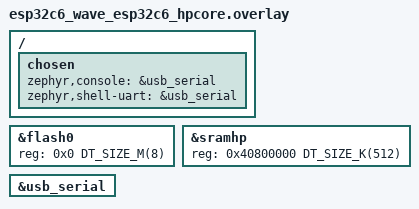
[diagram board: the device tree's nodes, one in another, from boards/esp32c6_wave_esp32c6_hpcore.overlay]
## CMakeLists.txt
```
# SPDX-License-Identifier: Apache-2.0

cmake_minimum_required(VERSION 3.20.0)

find_package(Zephyr REQUIRED HINTS $ENV{ZEPHYR_BASE})
project(ble_multitouch_sim)

target_sources(app PRIVATE src/main.c src/ble_rc.c src/touch_ipc.c)
```

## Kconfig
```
# SPDX-License-Identifier: Apache-2.0

mainmenu "BLE multi-touch simulator"

source "Kconfig.zephyr"
```

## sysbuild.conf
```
# ----> build/mcuboot/zephyr/.config.sysbuild
SB_CONFIG_MCUBOOT_MODE_OVERWRITE_ONLY=y
# SB_CONFIG_MCUBOOT_MODE_SWAP_USING_MOVE=y
# DIRECT_XIP will build two image for slot0 and slot1 for diff ADDR off 
# SB_CONFIG_MCUBOOT_MODE_DIRECT_XIP=y
# SB_CONFIG_MCUBOOT_MODE_DIRECT_XIP_WITH_REVERT=y
```

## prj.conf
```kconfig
CONFIG_BT=y
CONFIG_BT_PERIPHERAL=y
CONFIG_BT_SMP=y
CONFIG_BT_BONDABLE=y
CONFIG_BT_SETTINGS=y
CONFIG_SETTINGS=y
CONFIG_BT_BUF_ACL_TX_COUNT=8
CONFIG_BT_CONN_TX_MAX=8
CONFIG_BT_L2CAP_TX_BUF_COUNT=8
CONFIG_BT_DEVICE_NAME="Zephyr Multi-Touch"
CONFIG_BT_DEVICE_APPEARANCE=960
CONFIG_UART_NATIVE_PTY_0_ON_STDINOUT=y
CONFIG_SERIAL=y
CONFIG_SHELL=y
CONFIG_LOG=y
CONFIG_MAIN_STACK_SIZE=2048
CONFIG_SYS_CLOCK_TICKS_PER_SEC=1000

CONFIG_BT_HCI_ACL_FLOW_CONTROL=n
```

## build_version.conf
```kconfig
CONFIG_MCUBOOT_IMGTOOL_SIGN_VERSION="1.0.2+1019"
CONFIG_CUSTOM_VERSION="1.0.2"
CONFIG_CUSTOM_BUILD_NUMBER="1019"
```

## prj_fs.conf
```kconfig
# lyj config
CONFIG_WIFI_STA_EN=y

# Wi-Fi Configuration
CONFIG_WIFI=y
CONFIG_NET_L2_WIFI_SHELL=y
CONFIG_WIFI_NM=y
CONFIG_WIFI_USAGE_MODE_STA=y

# Network Configuration
CONFIG_NET_CONFIG_AUTO_INIT=n
CONFIG_NET_CONNECTION_MANAGER=y
CONFIG_NET_DHCPV4=y
CONFIG_NET_DHCPV4_SERVER=y
CONFIG_NET_IF_MAX_IPV4_COUNT=2
CONFIG_NET_IF_MAX_IPV6_COUNT=2
CONFIG_NET_IPV4=y
CONFIG_NET_L2_ETHERNET=y
CONFIG_NET_L2_WIFI_MGMT=y
CONFIG_NET_MGMT=y
CONFIG_NET_MGMT_EVENT=y
CONFIG_NET_MGMT_EVENT_INFO=y
CONFIG_NET_MGMT_EVENT_QUEUE_SIZE=10
CONFIG_NET_MGMT_EVENT_STACK_SIZE=4096
CONFIG_NET_PKT_RX_COUNT=16
CONFIG_NET_PKT_TX_COUNT=16
CONFIG_NET_SOCKETS_SERVICE_STACK_SIZE=4096
CONFIG_NET_TCP=y
CONFIG_NET_UDP=y
CONFIG_NETWORKING=y

# LOG Configuration
CONFIG_NET_LOG=y
CONFIG_NET_DHCPV4_SERVER_LOG_LEVEL_DBG=y

# websock
# Networking config
CONFIG_NETWORKING=y
CONFIG_NET_IPV4=y
#CONFIG_NET_IPV6=y
CONFIG_NET_TCP=y
CONFIG_NET_SHELL=y
CONFIG_NET_STATISTICS=y

CONFIG_NET_SOCKETS=y
CONFIG_ZVFS_POLL_MAX=10

# Network driver config
CONFIG_TEST_RANDOM_GENERATOR=y

CONFIG_NET_CONFIG_SETTINGS=y
CONFIG_NET_CONFIG_NEED_IPV4=y

# HTTP & Websocket
CONFIG_HTTP_CLIENT=y
CONFIG_WEBSOCKET_CLIENT=y

# Network debug config
CONFIG_LOG=y
CONFIG_LOG_MODE_IMMEDIATE=y
# CONFIG_NET_LOG=y
# CONFIG_NET_SOCKETS_LOG_LEVEL_DBG=y
# CONFIG_NET_HTTP_LOG_LEVEL_DBG=y
# CONFIG_NET_WEBSOCKET_LOG_LEVEL_DBG=y
# CONFIG_NET_CONTEXT_LOG_LEVEL_DBG=y
# CONFIG_NET_TCP_LOG_LEVEL_DBG=y

CONFIG_MAIN_STACK_SIZE=4096
CONFIG_HEAP_MEM_POOL_SIZE=98304

CONFIG_REQUIRES_FULL_LIBC=y
CONFIG_POSIX_API=y
CONFIG_EVENTFD=y

# Crypto Base for websocket
CONFIG_MBEDTLS=y
CONFIG_MBEDTLS_BUILTIN=y
CONFIG_MBEDTLS_MD_C=y

# 针对新版本/PSA 架构 for websocket
CONFIG_MBEDTLS_PSA_CRYPTO_C=y
CONFIG_PSA_WANT_ALG_SHA_1=y

# 内存
CONFIG_MAIN_STACK_SIZE=4096
CONFIG_MBEDTLS_ENABLE_HEAP=y
CONFIG_MBEDTLS_HEAP_SIZE=8192

CONFIG_ESP_SPIRAM=y
CONFIG_SHARED_MULTI_HEAP=y
CONFIG_SPIRAM_MODE_OCT=y
CONFIG_SPIRAM_SPEED_80M=n
# spi 4-wire MODE : 40M
# CONFIG_SPIRAM_MODE_QUAD=y
# CONFIG_SPIRAM_SPEED_40M=y
CONFIG_ESP32S3_DATA_CACHE_64KB=y
CONFIG_ESP_SPIRAM_MEMTEST=y

CONFIG_ESP32_WIFI_NET_ALLOC_SPIRAM=y

CONFIG_ZVFS_EVENTFD_MAX=5
#CONFIG_ZVFS_OPEN_MAX=10
#CONFIG_POSIX_MAX_FDS=10


######################################
#           for BLE                  #
######################################
CONFIG_BT=y
CONFIG_BT_PERIPHERAL=y
CONFIG_BT_DEVICE_NAME="小米蓝牙语音遥控器"
CONFIG_BT_DEVICE_APPEARANCE=384

CONFIG_BT_SMP=y

CONFIG_SHELL=y
CONFIG_BT_SHELL=y

CONFIG_BT_L2CAP_TX_BUF_COUNT=10
CONFIG_BT_BUF_ACL_TX_COUNT=10

CONFIG_BT_DIS=y
CONFIG_BT_DIS_PNP=y
CONFIG_BT_DIS_PNP_VID_SRC=1
CONFIG_BT_DIS_PNP_VID=0x2717
CONFIG_BT_DIS_PNP_PID=0x32b8
CONFIG_BT_DIS_PNP_VER=0x0011

CONFIG_BT_RX_STACK_SIZE=4096
CONFIG_SYSTEM_WORKQUEUE_STACK_SIZE=4096
CONFIG_BT_BUF_ACL_TX_COUNT=12


CONFIG_JSON_LIBRARY=y

CONFIG_ESP32_SW_COEXIST_ENABLE=y
CONFIG_ESP32_BT_CTLR_COEX_PHY_CODED_TX_RX_TLIM_EN=y
CONFIG_ESP32_BT_CTLR_COEX_PHY_CODED_TX_RX_TLIM_DIS=n

#SD and FS
CONFIG_DISK_DRIVER_SDMMC=y
CONFIG_DISK_ACCESS=y        
CONFIG_FILE_SYSTEM=y
CONFIG_FILE_SYSTEM_SHELL=y
CONFIG_FAT_FILESYSTEM_ELM=y
CONFIG_FS_FATFS_LFN=y
CONFIG_FS_FATFS_MAX_LFN=32

# CONFIG_FILE_SYSTEM_LITTLEFS=y
# CONFIG_FS_LITTLEFS_BLK_DEV=y
# CONFIG_FS_LITTLEFS_FMP_DEV=n

# CONFIG_FS_LITTLEFS_READ_SIZE=512
# CONFIG_FS_LITTLEFS_PROG_SIZE=512
# CONFIG_FS_LITTLEFS_CACHE_SIZE=512
# CONFIG_FS_LITTLEFS_LOOKAHEAD_SIZE=32

# CONFIG_FS_LITTLEFS_NUM_FILES=4
# CONFIG_FS_LITTLEFS_NUM_DIRS=4

CONFIG_FS_LOG_LEVEL_DBG=y

CONFIG_PSA_CRYPTO=y
CONFIG_PSA_WANT_ALG_SHA_256=y

CONFIG_FLASH=y
CONFIG_FLASH_MAP=y
CONFIG_FLASH_SHELL=y
CONFIG_FLASH_MAP_SHELL=y


CONFIG_STREAM_FLASH=y
CONFIG_IMG_MANAGER=y
CONFIG_MCUBOOT_IMG_MANAGER=y
CONFIG_MCUBOOT_SHELL=y
CONFIG_MCUBOOT_BOOTLOADER_MODE_RAM_LOAD=y
CONFIG_MCUBOOT_BOOTLOADER_MODE_RAM_LOAD_WITH_REVERT=y

CONFIG_REBOOT=y

# CONFIG_MCUBOOT_BOOTLOADER_MODE_DIRECT_XIP=y
# CONFIG_MCUBOOT_BOOTLOADER_MODE_DIRECT_XIP_WITH_REVERT=y
```

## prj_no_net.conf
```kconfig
CONFIG_WIFI_STA_EN=n
#
CONFIG_ZVFS_POLL_MAX=10

# Debug config
CONFIG_LOG=y
CONFIG_LOG_MODE_IMMEDIATE=y
# CONFIG_NET_LOG=y
# CONFIG_NET_SOCKETS_LOG_LEVEL_DBG=y
# CONFIG_NET_HTTP_LOG_LEVEL_DBG=y
# CONFIG_NET_WEBSOCKET_LOG_LEVEL_DBG=y
# CONFIG_NET_CONTEXT_LOG_LEVEL_DBG=y
# CONFIG_NET_TCP_LOG_LEVEL_DBG=y

CONFIG_MAIN_STACK_SIZE=4096
CONFIG_HEAP_MEM_POOL_SIZE=65536

CONFIG_REQUIRES_FULL_LIBC=y
CONFIG_POSIX_API=y
CONFIG_EVENTFD=y

# Crypto Base for websocket
CONFIG_MBEDTLS=y
CONFIG_MBEDTLS_BUILTIN=y
CONFIG_MBEDTLS_MD_C=y

# 针对新版本/PSA 架构 for websocket
CONFIG_MBEDTLS_PSA_CRYPTO_C=y
CONFIG_PSA_WANT_ALG_SHA_1=y

# 内存
CONFIG_MAIN_STACK_SIZE=4096
CONFIG_MBEDTLS_ENABLE_HEAP=y
CONFIG_MBEDTLS_HEAP_SIZE=8192

CONFIG_HEAP_MEM_POOL_SIZE=98304

CONFIG_ESP_SPIRAM=y
CONFIG_SHARED_MULTI_HEAP=y
CONFIG_SPIRAM_MODE_OCT=y
CONFIG_SPIRAM_SPEED_80M=y
CONFIG_ESP32S3_DATA_CACHE_64KB=y
CONFIG_ESP_SPIRAM_MEMTEST=y

CONFIG_ESP32_WIFI_NET_ALLOC_SPIRAM=y

CONFIG_ZVFS_EVENTFD_MAX=5
#CONFIG_ZVFS_OPEN_MAX=10
#CONFIG_POSIX_MAX_FDS=10


######################################
#           for BLE                  #
######################################
CONFIG_BT=y
CONFIG_BT_PERIPHERAL=y
CONFIG_BT_DEVICE_NAME="小米蓝牙语音遥控器"
CONFIG_BT_DEVICE_APPEARANCE=384

CONFIG_BT_SMP=y

CONFIG_SHELL=y
CONFIG_BT_SHELL=y

CONFIG_BT_L2CAP_TX_BUF_COUNT=10
CONFIG_BT_BUF_ACL_TX_COUNT=10

CONFIG_BT_DIS=y
CONFIG_BT_DIS_PNP=y
CONFIG_BT_DIS_PNP_VID_SRC=1
CONFIG_BT_DIS_PNP_VID=0x2717
CONFIG_BT_DIS_PNP_PID=0x32b8
CONFIG_BT_DIS_PNP_VER=0x0011

CONFIG_BT_RX_STACK_SIZE=4096
CONFIG_SYSTEM_WORKQUEUE_STACK_SIZE=4096
CONFIG_BT_BUF_ACL_TX_COUNT=12
```

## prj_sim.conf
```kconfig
# lyj config
CONFIG_WIFI_STA_EN=n


CONFIG_MAIN_STACK_SIZE=4096
CONFIG_HEAP_MEM_POOL_SIZE=65536

CONFIG_REQUIRES_FULL_LIBC=y
CONFIG_POSIX_API=y
CONFIG_EVENTFD=y

# Crypto Base for websocket
CONFIG_MBEDTLS=y
CONFIG_MBEDTLS_BUILTIN=y
CONFIG_MBEDTLS_MD_C=y

# 针对新版本/PSA 架构 for websocket
CONFIG_MBEDTLS_PSA_CRYPTO_C=y
CONFIG_PSA_WANT_ALG_SHA_1=y

# 内存
CONFIG_MAIN_STACK_SIZE=4096
CONFIG_MBEDTLS_ENABLE_HEAP=y
CONFIG_MBEDTLS_HEAP_SIZE=8192

CONFIG_HEAP_MEM_POOL_SIZE=98304

CONFIG_ZVFS_EVENTFD_MAX=5
#CONFIG_ZVFS_OPEN_MAX=10
#CONFIG_POSIX_MAX_FDS=10


######################################
#           for BLE                  #
######################################
CONFIG_BT=y
CONFIG_BT_PERIPHERAL=y
CONFIG_BT_DEVICE_NAME="小米蓝牙语音遥控器"
CONFIG_BT_DEVICE_APPEARANCE=384

CONFIG_BT_SMP=y

CONFIG_UART_NATIVE_PTY_0_ON_STDINOUT=y
CONFIG_SHELL=y
CONFIG_BT_SHELL=y

CONFIG_BT_L2CAP_TX_BUF_COUNT=10


CONFIG_BT_DIS=y
CONFIG_BT_DIS_PNP=y
CONFIG_BT_DIS_PNP_VID_SRC=1
CONFIG_BT_DIS_PNP_VID=0x2717
CONFIG_BT_DIS_PNP_PID=0x32b8
CONFIG_BT_DIS_PNP_VER=0x0011

CONFIG_BT_RX_STACK_SIZE=4096
CONFIG_SYSTEM_WORKQUEUE_STACK_SIZE=4096
CONFIG_BT_BUF_ACL_TX_COUNT=12
CONFIG_BT_BUF_EVT_RX_COUNT=16

CONFIG_BT_HCI_ACL_FLOW_CONTROL=n
CONFIG_BT_BUF_ACL_RX_SIZE=4096
CONFIG_BT_BUF_ACL_TX_SIZE=4096


CONFIG_JSON_LIBRARY=y
```

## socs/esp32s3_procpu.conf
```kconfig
CONFIG_WIFI_ESP32=y

# apsta_mode configuration
CONFIG_WIFI_SAMPLE_SSID="ACX2"
CONFIG_WIFI_SAMPLE_PSK="reinao802"
CONFIG_NET_CONFIG_PEER_IPV4_ADDR="192.168.66.155"
# CONFIG_WIFI_SAMPLE_SSID="1BE-2"
# CONFIG_WIFI_SAMPLE_PSK="12345678"
# CONFIG_NET_CONFIG_PEER_IPV4_ADDR="192.168.9.245"
#CONFIG_NET_CONFIG_HTTP_SRV_ADDR
```

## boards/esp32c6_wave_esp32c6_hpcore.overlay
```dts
/ {
	chosen {
		zephyr,console = &usb_serial;
		zephyr,shell-uart = &usb_serial;
	};
};

&flash0 {
    reg = <0x0 DT_SIZE_M(8)>;
};

&sramhp {
	reg = <0x40800000 DT_SIZE_K(512)>;
};

&usb_serial {
	status = "okay";
};
```

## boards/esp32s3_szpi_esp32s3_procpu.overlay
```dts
/ {
	chosen {
		zephyr,console = &usb_serial;
		zephyr,shell-uart = &usb_serial;
	};
};

&flash0 {
    reg = <0x0 DT_SIZE_M(16)>;
};

&psram0 {
        size = <DT_SIZE_M(8)>;
};

&usb_serial {
	status = "okay";
};
```

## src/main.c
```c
/* SPDX-License-Identifier: Apache-2.0 */

#include <zephyr/kernel.h>
#include <zephyr/logging/log.h>

#include "touch_hid.h"
#include "touch_ipc.h"

LOG_MODULE_REGISTER(main, LOG_LEVEL_INF);

int main(void)
{
	int err;

	LOG_INF("BLE multi-touch simulator starting");
	err = touch_hid_init();
	if (err) {
		LOG_ERR("Unable to start touch HID service: %d", err);
		return err;
	}

	err = touch_ipc_init();
	if (err) {
		LOG_ERR("Unable to start touch input IPC: %d", err);
		return err;
	}

	return 0;
}
```

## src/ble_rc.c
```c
/* SPDX-License-Identifier: Apache-2.0 */

#include <errno.h>
#include <stdlib.h>
#include <string.h>

#include <zephyr/bluetooth/bluetooth.h>
#include <zephyr/bluetooth/conn.h>
#include <zephyr/bluetooth/gatt.h>
#include <zephyr/bluetooth/uuid.h>
#include <zephyr/kernel.h>
#include <zephyr/logging/log.h>
#include <zephyr/shell/shell.h>
#include <zephyr/settings/settings.h>

#include "touch_hid.h"

LOG_MODULE_REGISTER(touch_hid, LOG_LEVEL_INF);

#define TOUCH_REPORT_ID 1
#define TOUCH_CONTACTS  3

struct hid_info {
	uint16_t bcd_hid;
	uint8_t country_code;
	uint8_t flags;
} __packed;

struct hid_report_ref {
	uint8_t id;
	uint8_t type;
} __packed;

struct touch_contact {
	uint8_t flags;
	uint8_t id;
	uint16_t x;
	uint16_t y;
} __packed;

struct touch_report {
	struct touch_contact contact[TOUCH_CONTACTS];
	uint8_t contact_count;
} __packed;

BUILD_ASSERT(sizeof(struct touch_report) == 19,
	     "The touch report must fit in the default 23-byte ATT MTU");

static const struct hid_info hid_info = {
	.bcd_hid = 0x0111,
	.country_code = 0,
	.flags = 0x03,
};

static const struct hid_report_ref input_report_ref = {
	.id = TOUCH_REPORT_ID,
	.type = 0x01,
};

/*
 * Report ID 1 contains three independent finger collections followed by the
 * total number of active contacts. The resulting 19-byte report fits in the
 * default 23-byte ATT MTU, so it works before a phone requests a larger MTU.
 * Coordinates use the 0..32767 HID range.
 */
static const uint8_t report_map[] = {
	0x05, 0x0d, 0x09, 0x04, 0xa1, 0x01, 0x85, TOUCH_REPORT_ID,
#define FINGER_COLLECTION \
	0x05, 0x0d, \
	0x09, 0x22, 0xa1, 0x02, \
	0x09, 0x42, 0x15, 0x00, 0x25, 0x01, 0x75, 0x01, 0x95, 0x01, 0x81, 0x02, \
	0x09, 0x32, 0x15, 0x00, 0x25, 0x01, 0x75, 0x01, 0x95, 0x01, 0x81, 0x02, \
	0x75, 0x06, 0x95, 0x01, 0x81, 0x03, \
	0x09, 0x51, 0x15, 0x00, 0x25, TOUCH_CONTACTS - 1, 0x75, 0x08, 0x95, 0x01, 0x81, 0x02, \
	0x05, 0x01, 0x09, 0x30, 0x16, 0x00, 0x00, 0x26, 0xff, 0x7f, 0x75, 0x10, 0x95, 0x01, 0x81, 0x02, \
	0x09, 0x31, 0x16, 0x00, 0x00, 0x26, 0xff, 0x7f, 0x75, 0x10, 0x95, 0x01, 0x81, 0x02, \
	0xc0
	FINGER_COLLECTION,
	FINGER_COLLECTION,
	FINGER_COLLECTION,
#undef FINGER_COLLECTION
	0x05, 0x0d, 0x09, 0x54, 0x15, 0x00, 0x25, TOUCH_CONTACTS,
	0x75, 0x08, 0x95, 0x01, 0x81, 0x02, 0xc0,
};

static struct touch_report touch_report;
/* Logical slots retain their Contact IDs. */
static struct touch_contact touch_state[TOUCH_CONTACTS];
static bool notifications_enabled;
static uint8_t control_point;
static struct bt_conn *active_conn;

static void advertising_work_handler(struct k_work *work);
K_WORK_DELAYABLE_DEFINE(advertising_work, advertising_work_handler);

static ssize_t read_hid_info(struct bt_conn *conn, const struct bt_gatt_attr *attr,
			     void *buf, uint16_t len, uint16_t offset)
{
	return bt_gatt_attr_read(conn, attr, buf, len, offset, &hid_info, sizeof(hid_info));
}

static ssize_t read_report_map(struct bt_conn *conn, const struct bt_gatt_attr *attr,
			       void *buf, uint16_t len, uint16_t offset)
{
	return bt_gatt_attr_read(conn, attr, buf, len, offset, report_map, sizeof(report_map));
}

static ssize_t read_report_ref(struct bt_conn *conn, const struct bt_gatt_attr *attr,
			       void *buf, uint16_t len, uint16_t offset)
{
	return bt_gatt_attr_read(conn, attr, buf, len, offset, &input_report_ref,
				 sizeof(input_report_ref));
}

static ssize_t read_input_report(struct bt_conn *conn, const struct bt_gatt_attr *attr,
				  void *buf, uint16_t len, uint16_t offset)
{
	return bt_gatt_attr_read(conn, attr, buf, len, offset, &touch_report,
				 sizeof(touch_report));
}

static void input_ccc_changed(const struct bt_gatt_attr *attr, uint16_t value)
{
	notifications_enabled = (value == BT_GATT_CCC_NOTIFY);
	LOG_INF("Touch notifications %s", notifications_enabled ? "enabled" : "disabled");
}

static ssize_t write_control_point(struct bt_conn *conn, const struct bt_gatt_attr *attr,
				   const void *buf, uint16_t len, uint16_t offset,
				   uint8_t flags)
{
	if (offset != 0 || len != 1) {
		return BT_GATT_ERR(BT_ATT_ERR_INVALID_ATTRIBUTE_LEN);
	}

	control_point = ((const uint8_t *)buf)[0];
	return len;
}

BT_GATT_SERVICE_DEFINE(hid_service,
	BT_GATT_PRIMARY_SERVICE(BT_UUID_HIDS),
	BT_GATT_CHARACTERISTIC(BT_UUID_HIDS_INFO, BT_GATT_CHRC_READ,
			       BT_GATT_PERM_READ, read_hid_info, NULL, NULL),
	BT_GATT_CHARACTERISTIC(BT_UUID_HIDS_REPORT_MAP, BT_GATT_CHRC_READ,
			       BT_GATT_PERM_READ_ENCRYPT, read_report_map, NULL, NULL),
	BT_GATT_CHARACTERISTIC(BT_UUID_HIDS_REPORT, BT_GATT_CHRC_READ | BT_GATT_CHRC_NOTIFY,
			       BT_GATT_PERM_READ_ENCRYPT, read_input_report, NULL, NULL),
	BT_GATT_CCC(input_ccc_changed, BT_GATT_PERM_READ_ENCRYPT | BT_GATT_PERM_WRITE_ENCRYPT),
	BT_GATT_DESCRIPTOR(BT_UUID_HIDS_REPORT_REF, BT_GATT_PERM_READ_ENCRYPT,
			   read_report_ref, NULL, NULL),
	BT_GATT_CHARACTERISTIC(BT_UUID_HIDS_CTRL_POINT, BT_GATT_CHRC_WRITE_WITHOUT_RESP,
			       BT_GATT_PERM_WRITE_ENCRYPT, NULL, write_control_point, &control_point)
);

static const struct bt_data ad[] = {
	BT_DATA_BYTES(BT_DATA_FLAGS, BT_LE_AD_GENERAL | BT_LE_AD_NO_BREDR),
	BT_DATA_BYTES(BT_DATA_UUID16_ALL, BT_UUID_16_ENCODE(BT_UUID_HIDS_VAL)),
	BT_DATA_BYTES(BT_DATA_GAP_APPEARANCE, 0xc0, 0x03),
};

static const struct bt_data sd[] = {
	BT_DATA(BT_DATA_NAME_COMPLETE, CONFIG_BT_DEVICE_NAME, sizeof(CONFIG_BT_DEVICE_NAME) - 1),
};

static void start_advertising(void)
{
	int err = bt_le_adv_start(BT_LE_ADV_CONN_FAST_1, ad, ARRAY_SIZE(ad), sd, ARRAY_SIZE(sd));

	if (err) {
		LOG_ERR("Advertising failed: %d", err);
	} else {
		LOG_INF("Advertising as %s", CONFIG_BT_DEVICE_NAME);
	}
}

static void advertising_work_handler(struct k_work *work)
{
	ARG_UNUSED(work);
	start_advertising();
}

static void connected(struct bt_conn *conn, uint8_t err)
{
	if (err) {
		LOG_ERR("Connection failed: 0x%02x", err);
		k_work_reschedule(&advertising_work, K_MSEC(200));
		return;
	}

	active_conn = bt_conn_ref(conn);
	LOG_INF("Host connected");
	err = bt_conn_set_security(conn, BT_SECURITY_L2);
	if (err) {
		LOG_ERR("Could not request encryption: %d", err);
	}
}

static void disconnected(struct bt_conn *conn, uint8_t reason)
{
	ARG_UNUSED(conn);
	notifications_enabled = false;
	if (active_conn != NULL) {
		bt_conn_unref(active_conn);
		active_conn = NULL;
	}
	LOG_INF("Host disconnected: 0x%02x", reason);
	/* Let the controller retire the disconnect command before advertising. */
	k_work_reschedule(&advertising_work, K_MSEC(200));
}

static void security_changed(struct bt_conn *conn, bt_security_t level,
			     enum bt_security_err err)
{
	ARG_UNUSED(conn);
	if (err) {
		LOG_ERR("Pairing/encryption failed: %s", bt_security_err_to_str(err));
	} else {
		LOG_INF("Link encrypted (security level %u)", level);
	}
}

BT_CONN_CB_DEFINE(conn_callbacks) = {
	.connected = connected,
	.disconnected = disconnected,
	.security_changed = security_changed,
};

int touch_hid_send(uint8_t slot, bool down, uint16_t x, uint16_t y)
{
	struct touch_contact *contact;
	size_t report_contacts = 0;
	int err;

	if (slot >= TOUCH_CONTACTS || x > 32767 || y > 32767) {
		return -EINVAL;
	}

	contact = &touch_state[slot];
	contact->flags = down ? BIT(0) | BIT(1) : 0;
	contact->id = slot;
	contact->x = x;
	contact->y = y;

	/*
	 * Android consumes only the first Contact Count finger collections.  The
	 * physical order in this fixed-size report must therefore not be the
	 * logical slot number: an isolated slot 2 contact has to be record 0.
	 */
	memset(&touch_report, 0, sizeof(touch_report));
	if (!down) {
		touch_report.contact[report_contacts++] = *contact;
	}
	for (size_t i = 0; i < TOUCH_CONTACTS; i++) {
		if (touch_state[i].flags & BIT(0)) {
			touch_report.contact[report_contacts++] = touch_state[i];
		}
	}
	touch_report.contact_count = report_contacts;

	if (active_conn == NULL || !notifications_enabled) {
		return -ENOTCONN;
	}

	/* The input-report value attribute is index 6 in this fixed service. */
	err = bt_gatt_notify(active_conn, &hid_service.attrs[6], &touch_report,
			     sizeof(touch_report));
	return err;
}

static int cmd_touch(const struct shell *sh, size_t argc, char **argv)
{
	char *end;
	unsigned long slot;
	unsigned long down;
	unsigned long x;
	unsigned long y;
	int err;

	if (argc != 5) {
		shell_error(sh, "usage: touch <slot 0-2> <down 0|1> <x 0-32767> <y 0-32767>");
		return -EINVAL;
	}

	slot = strtoul(argv[1], &end, 0); if (*end) return -EINVAL;
	down = strtoul(argv[2], &end, 0); if (*end || down > 1) return -EINVAL;
	x = strtoul(argv[3], &end, 0); if (*end || x > 32767) return -EINVAL;
	y = strtoul(argv[4], &end, 0); if (*end || y > 32767) return -EINVAL;
	err = touch_hid_send(slot, down, x, y);
	if (err) {
		shell_error(sh, "report not sent: %d", err);
	} else {
		shell_print(sh, "slot %lu %s at %lu,%lu", slot, down ? "down" : "up", x, y);
	}
	return err;
}

SHELL_CMD_REGISTER(touch, NULL, "Send touch: touch <slot> <down> <x> <y>", cmd_touch);

int touch_hid_init(void)
{
	int err = bt_enable(NULL);

	if (err) {
		return err;
	}

	if (IS_ENABLED(CONFIG_SETTINGS)) {
		err = settings_load();
		if (err) {
			LOG_ERR("Unable to load Bluetooth settings: %d", err);
			return err;
		}
	}

	for (size_t i = 0; i < TOUCH_CONTACTS; i++) {
		touch_state[i].id = i;
	}

	start_advertising();
	return 0;
}
```

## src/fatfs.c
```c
/*
 * Copyright (c) 2019 Tavish Naruka <tavishnaruka@gmail.com>
 * Copyright (c) 2023 Nordic Semiconductor ASA
 * Copyright (c) 2023 Antmicro <www.antmicro.com>
 *
 * SPDX-License-Identifier: Apache-2.0
 */

/* Sample which uses the filesystem API and SDHC driver */

#include <zephyr/kernel.h>
#include <zephyr/device.h>
#include <zephyr/storage/disk_access.h>
#include <zephyr/logging/log.h>
#include <zephyr/fs/fs.h>


#include <ff.h>

/*
 *  Note the fatfs library is able to mount only strings inside _VOLUME_STRS
 *  in ffconf.h
 */
#define DISK_DRIVE_NAME "SD"

#define DISK_MOUNT_PT "/"DISK_DRIVE_NAME":"

static FATFS fat_fs;
/* mounting info */
static struct fs_mount_t mp = {
	.type = FS_FATFS,
	.fs_data = &fat_fs,
};

#define FS_RET_OK FR_OK

LOG_MODULE_REGISTER(myfatfs);

#define MAX_PATH 128
#define SOME_FILE_NAME "some.dat"
#define SOME_DIR_NAME "some"
#define SOME_REQUIRED_LEN MAX(sizeof(SOME_FILE_NAME), sizeof(SOME_DIR_NAME))

static int lsdir(const char *path);

static bool create_some_entries(const char *base_path)
{
	char path[MAX_PATH];
	struct fs_file_t file;
	int base = strlen(base_path);

	fs_file_t_init(&file);

	if (base >= (sizeof(path) - SOME_REQUIRED_LEN)) {
		LOG_ERR("Not enough concatenation buffer to create file paths");
		return false;
	}

	LOG_INF("Creating some dir entries in %s", base_path);
	strncpy(path, base_path, sizeof(path));

	path[base++] = '/';
	path[base] = 0;
	strcat(&path[base], SOME_FILE_NAME);

	if (fs_open(&file, path, FS_O_CREATE) != 0) {
		LOG_ERR("Failed to create file %s", path);
		return false;
	}
	fs_close(&file);

	path[base] = 0;
	strcat(&path[base], SOME_DIR_NAME);

	if (fs_mkdir(path) != 0) {
		LOG_ERR("Failed to create dir %s", path);
		/* If code gets here, it has at least successes to create the
		 * file so allow function to return true.
		 */
	}
	return true;
}

static const char *disk_mount_pt = DISK_MOUNT_PT;

void fatfs_dump_disk_info(void)
{
	LOG_INF("DUMP DISK INFO ++++++++++++++++++++++++++++++");

	do {
		static const char *disk_pdrv = DISK_DRIVE_NAME;
		uint64_t memory_size_mb;
		uint32_t block_count;
		uint32_t block_size;

		if (disk_access_ioctl(disk_pdrv, DISK_IOCTL_CTRL_INIT, NULL) != 0) {
			LOG_ERR("Storage init ERROR!");
			break;
		}

		if (disk_access_ioctl(disk_pdrv, DISK_IOCTL_GET_SECTOR_COUNT, &block_count)) {
			LOG_ERR("Unable to get sector count");
			break;
		}
		LOG_INF("Block count %u", block_count);

		if (disk_access_ioctl(disk_pdrv, DISK_IOCTL_GET_SECTOR_SIZE, &block_size)) {
			LOG_ERR("Unable to get sector size");
			break;
		}
		LOG_INF("Sector size %u\n", block_size);

		memory_size_mb = (uint64_t)block_count * block_size; 
		
		LOG_INF("Memory Size(MB) %u\n", (uint32_t)(memory_size_mb >> 20));

		if (disk_access_ioctl(disk_pdrv, DISK_IOCTL_CTRL_DEINIT, NULL) != 0) {
			LOG_ERR("Storage deinit ERROR!");
			break;
		}
	} while (0);

	LOG_INF("DUMP DISK INFO ------------------------------");

	return;
}

int fatfs_init(void)
{
	// fatfs_dump_disk_info();
	mp.mnt_point = disk_mount_pt;

	if (fs_mount(&mp) != FS_RET_OK) {
		LOG_ERR("Error mounting disk.\n");
		return -1;
	}

	LOG_INF("Disk mounted.\n");

	if (lsdir(disk_mount_pt) == 0) {
		if (create_some_entries(disk_mount_pt)) {
			lsdir(disk_mount_pt);
		}
	}

	return 0;
}

void fatfs_fini(void)
{
	fs_unmount(&mp);

	return;
}

const char * fatfs_get_root_path(void)
{
	return disk_mount_pt;
}

/* List dir entry by path
 *
 * @param path Absolute path to list
 *
 * @return Negative errno code on error, number of listed entries on
 *         success.
 */
static int lsdir(const char *path)
{
	int res;
	struct fs_dir_t dirp;
	static struct fs_dirent entry;
	int count = 0;

	fs_dir_t_init(&dirp);

	/* Verify fs_opendir() */
	res = fs_opendir(&dirp, path);
	if (res) {
		printk("Error opening dir %s [%d]\n", path, res);
		return res;
	}

	printk("\nListing dir %s ...\n", path);
	for (;;) {
		/* Verify fs_readdir() */
		res = fs_readdir(&dirp, &entry);

		/* entry.name[0] == 0 means end-of-dir */
		if (res || entry.name[0] == 0) {
			break;
		}

		if (entry.type == FS_DIR_ENTRY_DIR) {
			printk("[DIR ] %s\n", entry.name);
		} else {
			printk("[FILE] %s (size = %zu)\n",
				entry.name, entry.size);
		}
		count++;
	}

	/* Verify fs_closedir() */
	fs_closedir(&dirp);
	if (res == 0) {
		res = count;
	}

	return res;
}
```

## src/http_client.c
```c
/*
 * Copyright (c) 2019 Intel Corporation
 *
 * SPDX-License-Identifier: Apache-2.0
 */

#include <zephyr/logging/log.h>
LOG_MODULE_REGISTER(HTTP_CLIENT, LOG_LEVEL_DBG);

#include <zephyr/posix/sys/socket.h>
#include <zephyr/posix/unistd.h>
#include <zephyr/posix/arpa/inet.h>

#include <zephyr/net/net_ip.h>
#include <zephyr/net/socket.h>
#include <zephyr/net/http/client.h>

#define HTTP_PORT 80

#if defined(CONFIG_NET_CONFIG_HTTP_SRV_ADDR)
#define SERVER_ADDR4  CONFIG_NET_CONFIG_HTTP_SRV_ADDR
#else
#define SERVER_ADDR4 "192.168.10.111"
#endif

#define MAX_RECV_BUF_LEN 512

static __attribute__ ((section (".ext_ram.bss"))) uint8_t recv_buf_ipv4[MAX_RECV_BUF_LEN];

static int setup_socket(const char *server, int port,
			            int *sock, struct sockaddr *addr, socklen_t addr_len)
{
	int ret = 0;

	memset(addr, 0, addr_len);

	net_sin(addr)->sin_family = AF_INET;
	net_sin(addr)->sin_port = htons(port);
	inet_pton(AF_INET, server, &net_sin(addr)->sin_addr);

	*sock = socket(AF_INET, SOCK_STREAM, IPPROTO_TCP);

	if (*sock < 0) {
		LOG_ERR("Failed to create IPv4 HTTP socket (%d)", -errno);
	}

	return ret;
}

#if 0
static int payload_cb(int sock, struct http_request *req, void *user_data)
{
	const char *content[] = {
		"foobar",
		"chunked",
		"last"
	};
	char tmp[64];
	int i, pos = 0;

	for (i = 0; i < ARRAY_SIZE(content); i++) {
		pos += snprintk(tmp + pos, sizeof(tmp) - pos,
				"%x\r\n%s\r\n",
				(unsigned int)strlen(content[i]),
				content[i]);
	}

	pos += snprintk(tmp + pos, sizeof(tmp) - pos, "0\r\n\r\n");

	(void)send(sock, tmp, pos, 0);

	return pos;
}
#endif

static int response_cb(struct http_response *rsp,
		       enum http_final_call final_data,
		       void *user_data)
{
	if (final_data == HTTP_DATA_MORE) {
		LOG_INF("Partial data received (%zd bytes)", rsp->data_len);
	} else if (final_data == HTTP_DATA_FINAL) {
		LOG_INF("All the data received (%zd bytes)", rsp->data_len);
	}

	LOG_INF("Response to %s", (const char *)user_data);
	LOG_INF("Response status %d:%s", rsp->http_status_code, rsp->http_status);
    rsp->recv_buf[rsp->data_len] = '\0';
    LOG_INF("Response data %s", (const char *)rsp->recv_buf);

	return 0;
}

static int connect_socket(const char *server, int port,
			              int *sock, struct sockaddr *addr, socklen_t addr_len)
{
	int ret;

	ret = setup_socket(server, port, sock, addr, addr_len);
	if (ret < 0 || *sock < 0) {
		return -1;
	}

    LOG_INF("try to connect to remote %s:%d", server, port);

	ret = connect(*sock, addr, addr_len);
	if (ret < 0) {
		LOG_ERR("Cannot connect to remote (%d)", -errno);
		close(*sock);
		*sock = -1;
		ret = -errno;
	}

	return ret;
}

int run_http_get_req(struct http_request *req, const char *server, int port)
{
	struct sockaddr_in addr4;
	int sock4 = -1;
	int32_t timeout = 3 * MSEC_PER_SEC;
	int ret = 0;

	(void)connect_socket(server, port,
				&sock4, (struct sockaddr *)&addr4,
				sizeof(addr4));
	if (sock4 < 0) {
		LOG_ERR("Cannot create HTTP IPv4 connection.");
		return -ECONNABORTED;
	}

	ret = http_client_req(sock4, req, timeout, "IPv4 GET");
	if (ret < 0) {
		LOG_ERR("Client error %d", ret);
	}

	close(sock4);
	sock4 = -1;

    return 0;
}

int run_get_SK_v(void)
{
    struct http_request req;

    memset(&req, 0, sizeof(req));

	req.method = HTTP_GET;
	req.url = "/get?value=Relay";
	req.host = SERVER_ADDR4;
	req.protocol = "HTTP/1.1";
	req.response = response_cb;
	req.recv_buf = recv_buf_ipv4;
	req.recv_buf_len = sizeof(recv_buf_ipv4);

    run_http_get_req(&req, SERVER_ADDR4, HTTP_PORT);

    return 0;
}

int run_set_SK_v(uint8_t v)
{
    struct http_request req;

    memset(&req, 0, sizeof(req));

	req.method = HTTP_GET;
    if (v == 0) {
        req.url = "/set?Relay=0";
    } else {
        req.url = "/set?Relay=1";
    }
	req.host = SERVER_ADDR4;
	req.protocol = "HTTP/1.1";
	req.response = response_cb;
	req.recv_buf = recv_buf_ipv4;
	req.recv_buf_len = sizeof(recv_buf_ipv4);

    run_http_get_req(&req, SERVER_ADDR4, HTTP_PORT);

    return 0;
}

int run_queries(void)
{
	struct sockaddr_in addr4;
	int sock4 = -1;
	int32_t timeout = 3 * MSEC_PER_SEC;
	int ret = 0;
	int port = HTTP_PORT;
	struct http_request req;

	/* Do a GET request */

	(void)connect_socket(SERVER_ADDR4, port,
				&sock4, (struct sockaddr *)&addr4,
				sizeof(addr4));
	if (sock4 < 0) {
		LOG_ERR("Cannot create HTTP IPv4 connection.");
		return -ECONNABORTED;
	}

	memset(&req, 0, sizeof(req));

	req.method = HTTP_GET;
	req.url = "/get?value=Relay";
	req.host = SERVER_ADDR4;
	req.protocol = "HTTP/1.1";
	req.response = response_cb;
	req.recv_buf = recv_buf_ipv4;
	req.recv_buf_len = sizeof(recv_buf_ipv4);

	ret = http_client_req(sock4, &req, timeout, "IPv4 GET");
	if (ret < 0) {
		LOG_ERR("Client error %d", ret);
	}

	close(sock4);
	sock4 = -1;

     #if 0

	/* Do a POST request */

	(void)connect_socket(SERVER_ADDR4, port,
				&sock4, (struct sockaddr *)&addr4,
				sizeof(addr4));
	if (sock4 < 0) {
		LOG_ERR("Cannot create HTTP IPv4 connection.");
		return -ECONNABORTED;
	}

	memset(&req, 0, sizeof(req));

	req.method = HTTP_POST;
	req.url = "/foobar";
	req.host = SERVER_ADDR4;
	req.protocol = "HTTP/1.1";
	req.payload = "foobar";
	req.payload_len = strlen(req.payload);
	req.response = response_cb;
	req.recv_buf = recv_buf_ipv4;
	req.recv_buf_len = sizeof(recv_buf_ipv4);

	ret = http_client_req(sock4, &req, timeout, "IPv4 POST");
	if (ret < 0) {
		LOG_ERR("Client error %d", ret);
	}

	close(sock4);
	sock4 = -1;

   
	/* Do a chunked POST request */

	const char *headers[] = {
		"Transfer-Encoding: chunked\r\n",
		NULL
	};

	(void)connect_socket(SERVER_ADDR4, port,
				&sock4, (struct sockaddr *)&addr4,
				sizeof(addr4));
	if (sock4 < 0) {
		LOG_ERR("Cannot create HTTP IPv4 connection.");
		return -ECONNABORTED;
	}

	memset(&req, 0, sizeof(req));

	req.method = HTTP_POST;
	req.url = "/chunked-test";
	req.host = SERVER_ADDR4;
	req.protocol = "HTTP/1.1";
	req.payload_cb = payload_cb;
	req.header_fields = headers;
	req.response = response_cb;
	req.recv_buf = recv_buf_ipv4;
	req.recv_buf_len = sizeof(recv_buf_ipv4);

	ret = http_client_req(sock4, &req, timeout, "IPv4 POST");
	if (ret < 0) {
		LOG_ERR("Client error %d", ret);
	}

	close(sock4);
    sock4 = -1;
    #endif

	return ret;
}
```

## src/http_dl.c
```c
/*
 * Copyright (c) 2019 Intel Corporation
 *
 * SPDX-License-Identifier: Apache-2.0
 */

#include <zephyr/logging/log.h>
LOG_MODULE_REGISTER(HTTP_DL, LOG_LEVEL_DBG);

#include <zephyr/posix/sys/socket.h>
#include <zephyr/posix/unistd.h>
#include <zephyr/posix/arpa/inet.h>
#include <zephyr/posix/netdb.h>

#include <zephyr/net/net_ip.h>
#include <zephyr/net/socket.h>
#include <zephyr/net/http/client.h>

#include <zephyr/shell/shell.h>

#include "wscli.h"

#define MAX_DL_RECV_BUF_LEN 1024

static __attribute__ ((section (".ext_ram.bss"))) uint8_t dl_recv_buf[MAX_DL_RECV_BUF_LEN];

struct download_ctx {
    struct fs_file_t file;       // 文件句柄
    const struct shell *sh;      // Shell 指针（用于在终端中输出）
    int64_t last_print_time;     // 上一次打印进度的时间戳
    size_t total_written;        // 已下载并写入的数据大小
    size_t total_size;           // 文件总大小（从 Content-Length 中获取）
    bool has_size;               // 是否成功获取到文件总大小
};

static int http_dl_socket_init(const char *hostname, const char *port,
			                   int *sock, struct sockaddr *addr, socklen_t addr_len)
{
	int ret = 0;
	struct addrinfo hints= {
		.ai_family = AF_INET,
		.ai_socktype = SOCK_STREAM,
		.ai_protocol = IPPROTO_TCP,
	};

	struct addrinfo *res = NULL;

	memset(addr, 0, addr_len);

	ret = getaddrinfo(hostname, port, &hints, &res);
	if (ret != 0) {
		LOG_ERR("Failed to getaddrinfo of %s:%s (%d)", hostname, port, -errno);
		return -1;
	}

	memcpy(addr, res->ai_addr, addr_len);

	*sock = socket(res->ai_family, res->ai_socktype, res->ai_protocol);
	if (*sock < 0) {
		LOG_ERR("Failed to create IPv4 HTTP socket (%d)", -errno);
	}

	return ret;
}

#if 0
static int http_dl_response_cb(struct http_response *rsp,
		       enum http_final_call final_data,
		       void *user_data)
{
	if (rsp->body_found && rsp->body_frag_len > 0) {
		struct fs_file_t *file = (struct fs_file_t *)user_data;
		ssize_t written = fs_write(file, rsp->body_frag_start, rsp->body_frag_len);
		if (written < 0) {
            LOG_ERR("wirte to file failed: %d", (int)written);
            return written;
        }
        LOG_DBG("write : %zu bytes", rsp->body_frag_len);
	}

	if (final_data == HTTP_DATA_MORE) {
		// LOG_INF("Partial data received (%zd bytes)", rsp->data_len);
	} else if (final_data == HTTP_DATA_FINAL) {
		LOG_INF("All the data received (%zd bytes)", rsp->data_len);
	}

	if (rsp->http_status_code != 200) {
		LOG_INF("Response Error: %d:%s", rsp->http_status_code, rsp->http_status);
	}
	

	return 0;
}

#else

static int http_dl_response_cb(struct http_response *rsp,
                               enum http_final_call final_data,
                               void *user_data)
{
    struct download_ctx *ctx = (struct download_ctx *)user_data;

    // 1. 尝试获取文件大小
    if (rsp->cl_present && !ctx->has_size) {
        ctx->total_size = rsp->content_length;
        ctx->has_size = true;
    }

    // 2. 写入文件并累加计数器
    if (rsp->body_found && rsp->body_frag_len > 0) {
        ssize_t written = fs_write(&ctx->file, rsp->body_frag_start, rsp->body_frag_len);
        if (written < 0) {
            return written;
        }
        ctx->total_written += rsp->body_frag_len;
    }

    // 3. 时间节流逻辑
    int64_t now = k_uptime_get(); // 获取当前系统毫秒数
    bool is_final = (final_data == HTTP_DATA_FINAL);

    // 限制：仅在【时间超过 1 秒】或【最后一次完成包】时才执行打印
    if (is_final || (now - ctx->last_print_time >= 1000)) {
        ctx->last_print_time = now;

        if (ctx->has_size && ctx->total_size > 0) {
            // 计算百分比
            int percent = (int)((uint64_t)ctx->total_written * 100 / ctx->total_size);
            if (percent > 100) percent = 100;

            // 构建一个简易的 ASCII 进度条 (宽度为 20 个字符)
            char bar[21];
            int filled = percent / 5; // 20格 * 5% = 100%
            for (int i = 0; i < 20; i++) {
                bar[i] = (i < filled) ? '=' : ' ';
            }
            bar[20] = '\0';

            // \r 使光标回到行首实现原地刷新，并在末尾留几个空格擦除可能存在的多余字符
            shell_fprintf(ctx->sh, SHELL_NORMAL, 
                          "\r[%s] %3d%% (%zu/%zu B)   ", 
                          bar, percent, ctx->total_written, ctx->total_size);
        } else {
            // 分块传输等未知大小的情况
            shell_fprintf(ctx->sh, SHELL_NORMAL, 
                          "\rDownloaded: %zu B...   ", 
                          ctx->total_written);
        }

        // 如果是最后一包，强制换行，让输出保持整齐
        if (is_final) {
            shell_fprintf(ctx->sh, SHELL_NORMAL, "\n[INFO] 下载完成。\n");
        }
    }

    return 0;
}

#endif

static int http_dl_socket_connect(const char *hostname, const char *port,
			                      int *sock, struct sockaddr *addr, socklen_t addr_len)
{
	int ret;

	ret = http_dl_socket_init(hostname, port, sock, addr, addr_len);
	if (ret < 0 || *sock < 0) {
		return -1;
	}

    LOG_INF("try to connect to remote %s:%s", hostname, port);

	ret = connect(*sock, addr, addr_len);
	if (ret < 0) {
		LOG_ERR("Cannot connect to remote (%d)", -errno);
		close(*sock);
		*sock = -1;
		ret = -errno;
	}

	return ret;
}

static int http_dl_get_req(struct http_request *req, const char *hostname, const char *port, void *user_data)
{
	struct sockaddr_in addr4;
	int sock4 = -1;
	int32_t timeout = 5 * 60 * MSEC_PER_SEC;
	int ret = 0;

	(void)http_dl_socket_connect(hostname, port, &sock4, (struct sockaddr *)&addr4, sizeof(addr4));
	if (sock4 < 0) {
		LOG_ERR("Cannot create HTTP IPv4 connection.");
		return -ECONNABORTED;
	}

	ret = http_client_req(sock4, req, timeout, user_data);
	if (ret < 0) {
		LOG_ERR("Client error %d", ret);
	}

	close(sock4);
	sock4 = -1;

    return 0;
}

int http_dl_file(const struct shell *sh, const char *hostname, const char *port, const char *path, const char *save_path)
{
	// struct fs_file_t file;
	struct download_ctx ctx = {
        .sh = sh,
        .last_print_time = 0,
        .total_written = 0,
        .total_size = 0,
        .has_size = false
    };
    fs_file_t_init(&(ctx.file));

	char full_path[128];
	const char * root_path = fatfs_get_root_path();

	snprintf(full_path, sizeof(full_path), "%s/%s", root_path, save_path);

    int ret = fs_open(&(ctx.file), full_path, FS_O_CREATE | FS_O_WRITE);
    if (ret < 0) {
        LOG_ERR("can not open %s: %d", full_path, ret);
        return ret;
    }

    struct http_request req;
    memset(&req, 0, sizeof(req));

	req.method = HTTP_GET;
    req.url = path;
	req.host = hostname;
	req.protocol = "HTTP/1.1";
	req.response = http_dl_response_cb;
	req.recv_buf = dl_recv_buf;
	req.recv_buf_len = sizeof(dl_recv_buf);

    http_dl_get_req(&req, hostname, port, &ctx);

	fs_close(&(ctx.file));

	unsigned char output_sha256[32] = {0};
	calculate_file_sha256(full_path, output_sha256);
	print_sha256_sum(output_sha256, full_path);

    return 0;
}

static int cmd_http_dl(const struct shell *sh, size_t argc, char **argv)
{
    if (argc < 5) return -EINVAL;

    const char *hostname  = argv[1];
    const char *port      = argv[2];
    const char *path      = argv[3];
    const char *save_path = argv[4];

    shell_print(sh, "download ...");
    shell_print(sh, "server: %s:%s", hostname, port);
    shell_print(sh, "URL Path: %s", path);
    shell_print(sh, "Save Path: %s", save_path);

    /* 调用下载引擎 */
    int ret = http_dl_file(sh, hostname, port, path, save_path);
    if (ret < 0) {
        shell_error(sh, "download failed : %d", ret);
        return ret;
    }

    shell_print(sh, "Download Success!");
    return 0;
}


SHELL_CMD_REGISTER(http_dl, NULL, 
	        		"Download file over HTTP\n"
        			"Usage: http_dl <hostname> <port> <path> <save_path>\n"
					"        http_dl 192.168.10.100 80 /dl/1.zip 1.zip"
					, cmd_http_dl);
```

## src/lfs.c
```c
/*
 * Copyright (c) 2022 Lukasz Majewski, DENX Software Engineering GmbH
 * Copyright (c) 2019 Peter Bigot Consulting, LLC
 *
 * SPDX-License-Identifier: Apache-2.0
 */

/* Sample which uses the filesystem API with littlefs */

#include <stdio.h>

#include <zephyr/kernel.h>
#include <zephyr/device.h>
#include <zephyr/fs/fs.h>
#include <zephyr/fs/littlefs.h>
#include <zephyr/logging/log.h>
#include <zephyr/storage/flash_map.h>

LOG_MODULE_REGISTER(main);

/* Matches LFS_NAME_MAX */
#define MAX_PATH_LEN 255
#define TEST_FILE_SIZE 547

static uint8_t file_test_pattern[TEST_FILE_SIZE];
static int lsdir(const char *path)
{
	int res;
	struct fs_dir_t dirp;
	static struct fs_dirent entry;

	fs_dir_t_init(&dirp);

	/* Verify fs_opendir() */
	res = fs_opendir(&dirp, path);
	if (res) {
		LOG_ERR("Error opening dir %s [%d]\n", path, res);
		return res;
	}

	LOG_PRINTK("\nListing dir %s ...\n", path);
	for (;;) {
		/* Verify fs_readdir() */
		res = fs_readdir(&dirp, &entry);

		/* entry.name[0] == 0 means end-of-dir */
		if (res || entry.name[0] == 0) {
			if (res < 0) {
				LOG_ERR("Error reading dir [%d]\n", res);
			}
			break;
		}

		if (entry.type == FS_DIR_ENTRY_DIR) {
			LOG_PRINTK("[DIR ] %s\n", entry.name);
		} else {
			LOG_PRINTK("[FILE] %s (size = %zu)\n",
				   entry.name, entry.size);
		}
	}

	/* Verify fs_closedir() */
	fs_closedir(&dirp);

	return res;
}

static int littlefs_increase_infile_value(char *fname)
{
	uint8_t boot_count = 0;
	struct fs_file_t file;
	int rc, ret;

	fs_file_t_init(&file);
	rc = fs_open(&file, fname, FS_O_CREATE | FS_O_RDWR);
	if (rc < 0) {
		LOG_ERR("FAIL: open %s: %d", fname, rc);
		return rc;
	}

	rc = fs_read(&file, &boot_count, sizeof(boot_count));
	if (rc < 0) {
		LOG_ERR("FAIL: read %s: [rd:%d]", fname, rc);
		goto out;
	}
	LOG_PRINTK("%s read count:%u (bytes: %d)\n", fname, boot_count, rc);

	rc = fs_seek(&file, 0, FS_SEEK_SET);
	if (rc < 0) {
		LOG_ERR("FAIL: seek %s: %d", fname, rc);
		goto out;
	}

	boot_count += 1;
	rc = fs_write(&file, &boot_count, sizeof(boot_count));
	if (rc < 0) {
		LOG_ERR("FAIL: write %s: %d", fname, rc);
		goto out;
	}

	LOG_PRINTK("%s write new boot count %u: [wr:%d]\n", fname,
		   boot_count, rc);

 out:
	ret = fs_close(&file);
	if (ret < 0) {
		LOG_ERR("FAIL: close %s: %d", fname, ret);
		return ret;
	}

	return (rc < 0 ? rc : 0);
}

static void incr_pattern(uint8_t *p, uint16_t size, uint8_t inc)
{
	uint8_t fill = 0x55;

	if (p[0] % 2 == 0) {
		fill = 0xAA;
	}

	for (int i = 0; i < (size - 1); i++) {
		if (i % 8 == 0) {
			p[i] += inc;
		} else {
			p[i] = fill;
		}
	}

	p[size - 1] += inc;
}

static void init_pattern(uint8_t *p, uint16_t size)
{
	uint8_t v = 0x1;

	memset(p, 0x55, size);

	for (int i = 0; i < size; i += 8) {
		p[i] = v++;
	}

	p[size - 1] = 0xAA;
}

static void print_pattern(uint8_t *p, uint16_t size)
{
	int i, j = size / 16, k;

	for (k = 0, i = 0; k < j; i += 16, k++) {
		LOG_PRINTK("%02x %02x %02x %02x %02x %02x %02x %02x ",
			   p[i], p[i+1], p[i+2], p[i+3],
			   p[i+4], p[i+5], p[i+6], p[i+7]);
		LOG_PRINTK("%02x %02x %02x %02x %02x %02x %02x %02x\n",
			   p[i+8], p[i+9], p[i+10], p[i+11],
			   p[i+12], p[i+13], p[i+14], p[i+15]);

		/* Mark 512B (sector) chunks of the test file */
		if ((k + 1) % 32 == 0) {
			LOG_PRINTK("\n");
		}
	}

	for (; i < size; i++) {
		LOG_PRINTK("%02x ", p[i]);
	}

	LOG_PRINTK("\n");
}

static int littlefs_binary_file_adj(char *fname)
{
	struct fs_dirent dirent;
	struct fs_file_t file;
	int rc, ret;

	/*
	 * Uncomment below line to force re-creation of the test pattern
	 * file on the littlefs FS.
	 */
	/* fs_unlink(fname); */
	fs_file_t_init(&file);

	rc = fs_open(&file, fname, FS_O_CREATE | FS_O_RDWR);
	if (rc < 0) {
		LOG_ERR("FAIL: open %s: %d", fname, rc);
		return rc;
	}

	rc = fs_stat(fname, &dirent);
	if (rc < 0) {
		LOG_ERR("FAIL: stat %s: %d", fname, rc);
		goto out;
	}

	/* Check if the file exists - if not just write the pattern */
	if (rc == 0 && dirent.type == FS_DIR_ENTRY_FILE && dirent.size == 0) {
		LOG_INF("Test file: %s not found, create one!",
			fname);
		init_pattern(file_test_pattern, sizeof(file_test_pattern));
	} else {
		rc = fs_read(&file, file_test_pattern,
			     sizeof(file_test_pattern));
		if (rc < 0) {
			LOG_ERR("FAIL: read %s: [rd:%d]",
				fname, rc);
			goto out;
		}
		incr_pattern(file_test_pattern, sizeof(file_test_pattern), 0x1);
	}

	LOG_PRINTK("------ FILE: %s ------\n", fname);
	print_pattern(file_test_pattern, sizeof(file_test_pattern));

	rc = fs_seek(&file, 0, FS_SEEK_SET);
	if (rc < 0) {
		LOG_ERR("FAIL: seek %s: %d", fname, rc);
		goto out;
	}

	rc = fs_write(&file, file_test_pattern, sizeof(file_test_pattern));
	if (rc < 0) {
		LOG_ERR("FAIL: write %s: %d", fname, rc);
	}

 out:
	ret = fs_close(&file);
	if (ret < 0) {
		LOG_ERR("FAIL: close %s: %d", fname, ret);
		return ret;
	}

	return (rc < 0 ? rc : 0);
}


static int littlefs_flash_erase(unsigned int id)
{
	const struct flash_area *pfa;
	int rc;

	rc = flash_area_open(id, &pfa);
	if (rc < 0) {
		LOG_ERR("FAIL: unable to find flash area %u: %d\n",
			id, rc);
		return rc;
	}

	LOG_PRINTK("Area %u at 0x%x on %s for %u bytes\n",
		   id, (unsigned int)pfa->fa_off, pfa->fa_dev->name,
		   (unsigned int)pfa->fa_size);

	/* Optional wipe flash contents */
	if (IS_ENABLED(CONFIG_APP_WIPE_STORAGE)) {
		rc = flash_area_flatten(pfa, 0, pfa->fa_size);
		LOG_ERR("Erasing flash area ... %d", rc);
	}

	flash_area_close(pfa);
	return rc;
}

#define DISK_NAME "SD"

struct fs_littlefs lfsfs;
static struct fs_mount_t __mp = {
	.type = FS_LITTLEFS,
	.fs_data = &lfsfs,
	.flags = FS_MOUNT_FLAG_USE_DISK_ACCESS,
};
struct fs_mount_t *mountpoint = &__mp;

static int littlefs_mount(struct fs_mount_t *mp)
{
	static const char *disk_mount_pt = "/"DISK_NAME":";
	static const char *disk_pdrv = DISK_NAME;

	mp->storage_dev = (void *)disk_pdrv;
	mp->mnt_point = disk_mount_pt;

	return fs_mount(mp);
}

int lfs_run(void)
{
	char fname1[MAX_PATH_LEN];
	char fname2[MAX_PATH_LEN];
	struct fs_statvfs sbuf;
	int rc;

	LOG_PRINTK("Sample program to r/w files on littlefs\n");

	rc = littlefs_mount(mountpoint);
	if (rc < 0) {
		return 0;
	}

	snprintf(fname1, sizeof(fname1), "%s/boot_count", mountpoint->mnt_point);
	snprintf(fname2, sizeof(fname2), "%s/pattern.bin", mountpoint->mnt_point);

	rc = fs_statvfs(mountpoint->mnt_point, &sbuf);
	if (rc < 0) {
		LOG_PRINTK("FAIL: statvfs: %d\n", rc);
		goto out;
	}

	LOG_PRINTK("%s: bsize = %lu ; frsize = %lu ;"
		   " blocks = %lu ; bfree = %lu\n",
		   mountpoint->mnt_point,
		   sbuf.f_bsize, sbuf.f_frsize,
		   sbuf.f_blocks, sbuf.f_bfree);

	rc = lsdir(mountpoint->mnt_point);
	if (rc < 0) {
		LOG_PRINTK("FAIL: lsdir %s: %d\n", mountpoint->mnt_point, rc);
		goto out;
	}

	rc = littlefs_increase_infile_value(fname1);
	if (rc) {
		goto out;
	}

	rc = littlefs_binary_file_adj(fname2);
	if (rc) {
		goto out;
	}

out:
	rc = fs_unmount(mountpoint);
	LOG_PRINTK("%s unmount: %d\n", mountpoint->mnt_point, rc);
	return 0;
}
```

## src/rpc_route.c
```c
#include <string.h>
#include <stdlib.h>

#include <zephyr/kernel.h>
#include <zephyr/logging/log.h>

#include "wscli.h"
#include "rpc_route.h"


/*
{
    "func":"ble_adv",
    "paras": [
        {"k":"duration", "v":"100"},
        {"k":"op", "v":"start"}
    ]
}
*/

#define MAX_PARAS 5 

struct parameter {
    const char *k;
    const char *v;
};

struct rpc_func {
    const char *func;
    struct parameter paras[MAX_PARAS]; // 静态数组
    size_t num_paras;                  // 用于保存实际解析出的数组元素个数 
};

static const struct json_obj_descr param_descr[] = {
    JSON_OBJ_DESCR_PRIM(struct parameter, k, JSON_TOK_STRING),
    JSON_OBJ_DESCR_PRIM(struct parameter, v, JSON_TOK_STRING),
};


static const struct json_obj_descr rpc_req_descr[] = {
    JSON_OBJ_DESCR_PRIM(struct rpc_func, func, JSON_TOK_STRING),
    /* 解析对象数组：指定最大容量、实际数量变量、以及内层描述符 */
    JSON_OBJ_DESCR_OBJ_ARRAY(struct rpc_func, paras, MAX_PARAS, num_paras, 
                             param_descr, ARRAY_SIZE(param_descr)),
};


static /* inline */ const char* get_v_by_k(struct parameter *paras, size_t num_paras, const char *key) {
    for (size_t i = 0; i < num_paras; i++) {
        if (strcmp(paras[i].k, key) == 0) {
            return paras[i].v;
        }
    }
    return NULL;
}

#define FUNC_ARGS_LIST struct parameter *paras, size_t num

#define DEBUG_PRINT_PARAMS do { \
    for (size_t _i = 0; _i < (num); _i++) { \
        printk("  [%zu] k: %s, v: %s\n", _i, (paras)[_i].k, (paras)[_i].v); \
    } \
} while(0)

#define GET_PARAM_REQUIRED(var_name, key) \
    const char *var_name = get_v_by_k(paras, num, key); \
    if (!var_name) { \
        printk("Error: Missing required parameter '%s'\n", key); \
        return; \
    }

#define GET_PARAM_OPTIONAL(var_name, key, default_val) \
    const char *var_name = get_v_by_k(paras, num, key); \
    if (!var_name) { \
        var_name = default_val; \
    }

int get_k_idx(struct parameter *paras, size_t num_paras, const char *key)
{
    for (size_t i = 0; i < num_paras; i++) {
        if (0 == strncmp(paras[i].k, key, strlen(key))) {
            return i;
        }
    }

    printk("get_k_idx: Cant not get [%s]!\n", key);
    return -1;
}

void func_ble_adv(FUNC_ARGS_LIST)
{
    /*
        {"k":"duration", "v":"100"},
        {"k":"op", "v":"start"},
        {"k":"mode", "v":"normal"} // normal / wakeup
    */

    DEBUG_PRINT_PARAMS;

    GET_PARAM_REQUIRED(op_str, "op");

    if (0 == strncmp(op_str, "start", 5)) {
        GET_PARAM_REQUIRED(duration_str, "duration");
        GET_PARAM_REQUIRED(mode_str, "mode");
        printk("start ble adv duration:%s, op:%s, mode:%s\n", duration_str, op_str, mode_str);
        bool isWakeup = false;
        if (0 == strncmp(mode_str, "wakeup", 6)) {
            isWakeup = true;
        }
        try_advertising_start(isWakeup, atoi(duration_str));
    } else if (0 == strncmp(op_str, "stop", 5)) {
        printk("stop ble adv\n");
        advertising_stop();
    }
}


struct rpc_route {
    const char *func_name;
    void (*handler)(struct parameter *paras, size_t num_paras);
};

static const struct rpc_route routes[] = {
    {"ble_adv", func_ble_adv},
    // {"set_wifi",      handle_set_wifi},
};

/* 
    * 【重要警告】: 
    * Zephyr 的 json_obj_parse() 在解析字符串时会修改原字符串（插入 '\0'），
    * 因此 JSON 数据必须存放在可读写的 RAM 中 (char [])，绝对不能是 const char * 
    */
void rpc_execute(char *json_str, size_t json_str_len)
{
    struct rpc_func req = {0}; // 初始化清零

    int ret = json_obj_parse(json_str, json_str_len, 
                             rpc_req_descr, ARRAY_SIZE(rpc_req_descr), 
                             &req);
    
    if (ret < 0 || req.func == NULL) {
        printk("RPC req parse failed. ret:%d\n", ret);
        return;
    }

    printk("RPC func: [%s]\n", req.func);

    for(int i=0; i < ARRAY_SIZE(routes); i++) {
        if (strcmp(req.func, routes[i].func_name) == 0) {
            routes[i].handler(req.paras, req.num_paras);
            break;
        }
    }

    return;
}
```

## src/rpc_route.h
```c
#ifndef __RPC_ROUTE__
#define __RPC_ROUTE__

#include <zephyr/data/json.h>

#endif // __RPC_ROUTE__
```

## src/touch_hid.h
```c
/* SPDX-License-Identifier: Apache-2.0 */

#ifndef TOUCH_HID_H_
#define TOUCH_HID_H_

#include <stdbool.h>
#include <stdint.h>

int touch_hid_init(void);
int touch_hid_send(uint8_t slot, bool down, uint16_t x, uint16_t y);

#endif /* TOUCH_HID_H_ */
```
